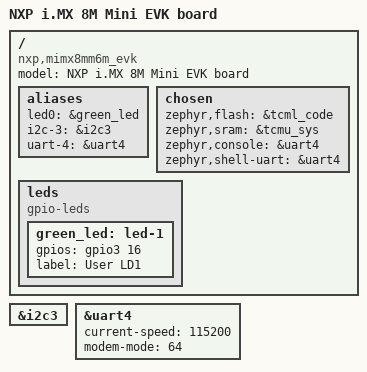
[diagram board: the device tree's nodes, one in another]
/*
 * Copyright (c) 2019, Manivannan Sadhasivam <mani@kernel.org>
 *
 * SPDX-License-Identifier: Apache-2.0
 */

/dts-v1/;

#include <nxp/nxp_imx8m_m4.dtsi>

/ {
	model = "NXP i.MX 8M Mini EVK board";
	compatible = "nxp,mimx8mm6m_evk";

	aliases {
		led0 = &green_led;
		i2c-3 = &i2c3;
		uart-4 = &uart4;
	};

	chosen {
		zephyr,flash = &tcml_code;
		zephyr,sram = &tcmu_sys;
		zephyr,console = &uart4;
		zephyr,shell-uart = &uart4;
	};

	leds {
		compatible = "gpio-leds";
		green_led: led-1 {
			gpios = <&gpio3 16 GPIO_INT_ACTIVE_HIGH>;
			label = "User LD1";
		};
	};
};

&i2c3 {
	status = "okay";
};

&uart4 {
	status = "okay";
	current-speed = <115200>;
	modem-mode = <64>;
};
